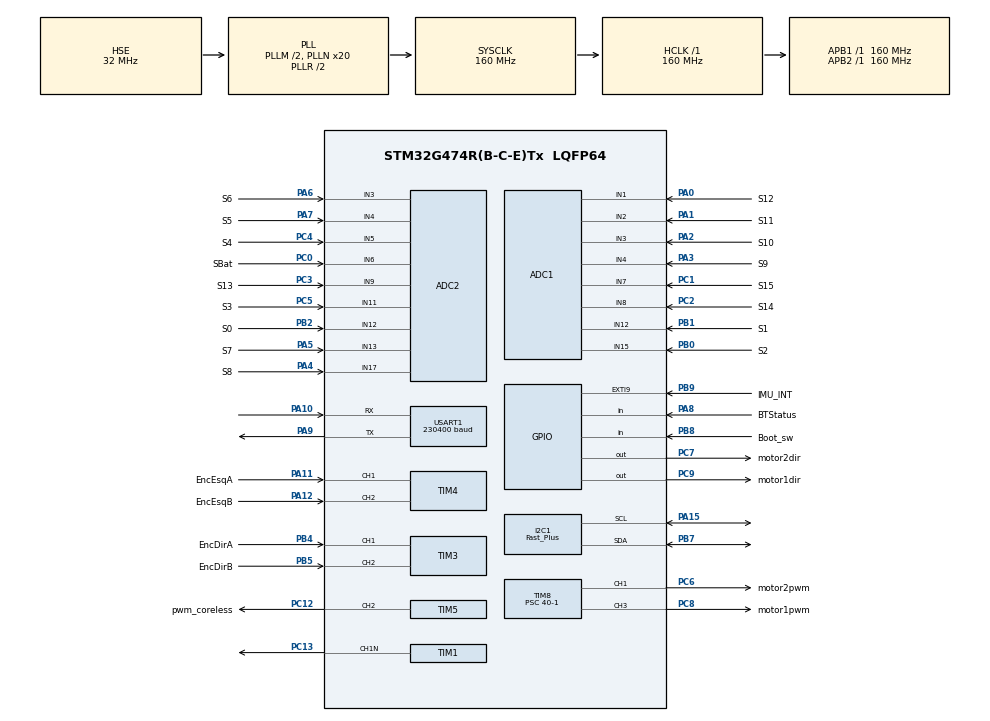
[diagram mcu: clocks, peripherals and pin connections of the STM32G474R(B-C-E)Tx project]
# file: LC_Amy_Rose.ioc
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ADC1.Channel-10\#ChannelRegularConversion=ADC_CHANNEL_VREFINT
ADC1.Channel-2\#ChannelRegularConversion=ADC_CHANNEL_1
ADC1.Channel-3\#ChannelRegularConversion=ADC_CHANNEL_2
ADC1.Channel-4\#ChannelRegularConversion=ADC_CHANNEL_3
ADC1.Channel-5\#ChannelRegularConversion=ADC_CHANNEL_4
ADC1.Channel-6\#ChannelRegularConversion=ADC_CHANNEL_7
ADC1.Channel-7\#ChannelRegularConversion=ADC_CHANNEL_8
ADC1.Channel-8\#ChannelRegularConversion=ADC_CHANNEL_12
ADC1.Channel-9\#ChannelRegularConversion=ADC_CHANNEL_15
ADC1.ContinuousConvMode=ENABLE
ADC1.DMAContinuousRequests=ENABLE
ADC1.NbrOfConversion=9
ADC1.NbrOfConversionFlag=1
ADC1.OffsetNumber-10\#ChannelRegularConversion=ADC_OFFSET_NONE
ADC1.OffsetNumber-2\#ChannelRegularConversion=ADC_OFFSET_NONE
ADC1.OffsetNumber-3\#ChannelRegularConversion=ADC_OFFSET_NONE
ADC1.OffsetNumber-4\#ChannelRegularConversion=ADC_OFFSET_NONE
ADC1.OffsetNumber-5\#ChannelRegularConversion=ADC_OFFSET_NONE
ADC1.OffsetNumber-6\#ChannelRegularConversion=ADC_OFFSET_NONE
ADC1.OffsetNumber-7\#ChannelRegularConversion=ADC_OFFSET_NONE
ADC1.OffsetNumber-8\#ChannelRegularConversion=ADC_OFFSET_NONE
ADC1.OffsetNumber-9\#ChannelRegularConversion=ADC_OFFSET_NONE
ADC1.Rank-10\#ChannelRegularConversion=9
ADC1.Rank-2\#ChannelRegularConversion=1
ADC1.Rank-3\#ChannelRegularConversion=2
ADC1.Rank-4\#ChannelRegularConversion=3
ADC1.Rank-5\#ChannelRegularConversion=4
ADC1.Rank-6\#ChannelRegularConversion=5
ADC1.Rank-7\#ChannelRegularConversion=6
ADC1.Rank-8\#ChannelRegularConversion=7
ADC1.Rank-9\#ChannelRegularConversion=8
ADC1.SamplingTime-10\#ChannelRegularConversion=ADC_SAMPLETIME_640CYCLES_5
ADC1.SamplingTime-2\#ChannelRegularConversion=ADC_SAMPLETIME_640CYCLES_5
ADC1.SamplingTime-3\#ChannelRegularConversion=ADC_SAMPLETIME_640CYCLES_5
ADC1.SamplingTime-4\#ChannelRegularConversion=ADC_SAMPLETIME_640CYCLES_5
ADC1.SamplingTime-5\#ChannelRegularConversion=ADC_SAMPLETIME_640CYCLES_5
ADC1.SamplingTime-6\#ChannelRegularConversion=ADC_SAMPLETIME_640CYCLES_5
ADC1.SamplingTime-7\#ChannelRegularConversion=ADC_SAMPLETIME_640CYCLES_5
ADC1.SamplingTime-8\#ChannelRegularConversion=ADC_SAMPLETIME_640CYCLES_5
ADC1.SamplingTime-9\#ChannelRegularConversion=ADC_SAMPLETIME_640CYCLES_5
ADC1.master=1
ADC2.Channel-0\#ChannelRegularConversion=ADC_CHANNEL_3
ADC2.Channel-1\#ChannelRegularConversion=ADC_CHANNEL_4
ADC2.Channel-2\#ChannelRegularConversion=ADC_CHANNEL_5
ADC2.Channel-3\#ChannelRegularConversion=ADC_CHANNEL_9
ADC2.Channel-4\#ChannelRegularConversion=ADC_CHANNEL_11
ADC2.Channel-5\#ChannelRegularConversion=ADC_CHANNEL_12
ADC2.Channel-6\#ChannelRegularConversion=ADC_CHANNEL_13
ADC2.Channel-7\#ChannelRegularConversion=ADC_CHANNEL_17
ADC2.Channel-8\#ChannelRegularConversion=ADC_CHANNEL_6
ADC2.ContinuousConvMode=ENABLE
ADC2.DMAContinuousRequests=ENABLE
ADC2.NbrOfConversion=9
ADC2.NbrOfConversionFlag=1
ADC2.OffsetNumber-0\#ChannelRegularConversion=ADC_OFFSET_NONE
ADC2.OffsetNumber-1\#ChannelRegularConversion=ADC_OFFSET_NONE
ADC2.OffsetNumber-2\#ChannelRegularConversion=ADC_OFFSET_NONE
ADC2.OffsetNumber-3\#ChannelRegularConversion=ADC_OFFSET_NONE
ADC2.OffsetNumber-4\#ChannelRegularConversion=ADC_OFFSET_NONE
ADC2.OffsetNumber-5\#ChannelRegularConversion=ADC_OFFSET_NONE
ADC2.OffsetNumber-6\#ChannelRegularConversion=ADC_OFFSET_NONE
ADC2.OffsetNumber-7\#ChannelRegularConversion=ADC_OFFSET_NONE
ADC2.OffsetNumber-8\#ChannelRegularConversion=ADC_OFFSET_NONE
ADC2.Rank-0\#ChannelRegularConversion=1
ADC2.Rank-1\#ChannelRegularConversion=2
ADC2.Rank-2\#ChannelRegularConversion=3
ADC2.Rank-3\#ChannelRegularConversion=4
ADC2.Rank-4\#ChannelRegularConversion=5
ADC2.Rank-5\#ChannelRegularConversion=6
ADC2.Rank-6\#ChannelRegularConversion=7
ADC2.Rank-7\#ChannelRegularConversion=8
ADC2.Rank-8\#ChannelRegularConversion=9
ADC2.SamplingTime-0\#ChannelRegularConversion=ADC_SAMPLETIME_640CYCLES_5
ADC2.SamplingTime-1\#ChannelRegularConversion=ADC_SAMPLETIME_640CYCLES_5
ADC2.SamplingTime-2\#ChannelRegularConversion=ADC_SAMPLETIME_640CYCLES_5
ADC2.SamplingTime-3\#ChannelRegularConversion=ADC_SAMPLETIME_640CYCLES_5
ADC2.SamplingTime-4\#ChannelRegularConversion=ADC_SAMPLETIME_640CYCLES_5
ADC2.SamplingTime-5\#ChannelRegularConversion=ADC_SAMPLETIME_640CYCLES_5
ADC2.SamplingTime-6\#ChannelRegularConversion=ADC_SAMPLETIME_640CYCLES_5
ADC2.SamplingTime-7\#ChannelRegularConversion=ADC_SAMPLETIME_640CYCLES_5
ADC2.SamplingTime-8\#ChannelRegularConversion=ADC_SAMPLETIME_640CYCLES_5
Dma.ADC1.0.Direction=DMA_PERIPH_TO_MEMORY
Dma.ADC1.0.EventEnable=DISABLE
Dma.ADC1.0.Instance=DMA1_Channel1
Dma.ADC1.0.MemDataAlignment=DMA_MDATAALIGN_WORD
Dma.ADC1.0.MemInc=DMA_MINC_ENABLE
Dma.ADC1.0.Mode=DMA_CIRCULAR
Dma.ADC1.0.PeriphDataAlignment=DMA_PDATAALIGN_WORD
Dma.ADC1.0.PeriphInc=DMA_PINC_DISABLE
Dma.ADC1.0.Polarity=HAL_DMAMUX_REQ_GEN_RISING
Dma.ADC1.0.Priority=DMA_PRIORITY_LOW
Dma.ADC1.0.RequestNumber=1
Dma.ADC1.0.SignalID=NONE
Dma.ADC1.0.SyncEnable=DISABLE
Dma.ADC1.0.SyncPolarity=HAL_DMAMUX_SYNC_NO_EVENT
Dma.ADC1.0.SyncRequestNumber=1
Dma.ADC1.0.SyncSignalID=NONE
Dma.ADC2.1.Direction=DMA_PERIPH_TO_MEMORY
Dma.ADC2.1.EventEnable=DISABLE
Dma.ADC2.1.Instance=DMA1_Channel2
Dma.ADC2.1.MemDataAlignment=DMA_MDATAALIGN_WORD
Dma.ADC2.1.MemInc=DMA_MINC_ENABLE
Dma.ADC2.1.Mode=DMA_CIRCULAR
Dma.ADC2.1.PeriphDataAlignment=DMA_PDATAALIGN_WORD
Dma.ADC2.1.PeriphInc=DMA_PINC_DISABLE
Dma.ADC2.1.Polarity=HAL_DMAMUX_REQ_GEN_RISING
Dma.ADC2.1.Priority=DMA_PRIORITY_LOW
Dma.ADC2.1.RequestNumber=1
Dma.ADC2.1.SignalID=NONE
Dma.ADC2.1.SyncEnable=DISABLE
Dma.ADC2.1.SyncPolarity=HAL_DMAMUX_SYNC_NO_EVENT
Dma.ADC2.1.SyncRequestNumber=1
Dma.ADC2.1.SyncSignalID=NONE
Dma.Request0=ADC1
Dma.Request1=ADC2
Dma.Request2=USART1_TX
Dma.Request3=USART1_RX
Dma.Request4=TIM1_CH1
Dma.TIM1_CH1.4.Direction=DMA_MEMORY_TO_PERIPH
Dma.TIM1_CH1.4.EventEnable=DISABLE
Dma.TIM1_CH1.4.Instance=DMA1_Channel5
Dma.TIM1_CH1.4.MemDataAlignment=DMA_MDATAALIGN_WORD
Dma.TIM1_CH1.4.MemInc=DMA_MINC_ENABLE
Dma.TIM1_CH1.4.Mode=DMA_NORMAL
Dma.TIM1_CH1.4.PeriphDataAlignment=DMA_PDATAALIGN_WORD
Dma.TIM1_CH1.4.PeriphInc=DMA_PINC_DISABLE
Dma.TIM1_CH1.4.Polarity=HAL_DMAMUX_REQ_GEN_RISING
Dma.TIM1_CH1.4.Priority=DMA_PRIORITY_LOW
Dma.TIM1_CH1.4.RequestNumber=1
Dma.TIM1_CH1.4.SignalID=NONE
Dma.TIM1_CH1.4.SyncEnable=DISABLE
Dma.TIM1_CH1.4.SyncPolarity=HAL_DMAMUX_SYNC_NO_EVENT
Dma.TIM1_CH1.4.SyncRequestNumber=1
Dma.TIM1_CH1.4.SyncSignalID=NONE
Dma.USART1_RX.3.Direction=DMA_PERIPH_TO_MEMORY
Dma.USART1_RX.3.EventEnable=DISABLE
Dma.USART1_RX.3.Instance=DMA1_Channel4
Dma.USART1_RX.3.MemDataAlignment=DMA_MDATAALIGN_BYTE
Dma.USART1_RX.3.MemInc=DMA_MINC_ENABLE
Dma.USART1_RX.3.Mode=DMA_NORMAL
Dma.USART1_RX.3.PeriphDataAlignment=DMA_PDATAALIGN_BYTE
Dma.USART1_RX.3.PeriphInc=DMA_PINC_DISABLE
Dma.USART1_RX.3.Polarity=HAL_DMAMUX_REQ_GEN_RISING
Dma.USART1_RX.3.Priority=DMA_PRIORITY_LOW
Dma.USART1_RX.3.RequestNumber=1
Dma.USART1_RX.3.SignalID=NONE
Dma.USART1_RX.3.SyncEnable=DISABLE
Dma.USART1_RX.3.SyncPolarity=HAL_DMAMUX_SYNC_NO_EVENT
Dma.USART1_RX.3.SyncRequestNumber=1
Dma.USART1_RX.3.SyncSignalID=NONE
Dma.USART1_TX.2.Direction=DMA_MEMORY_TO_PERIPH
Dma.USART1_TX.2.EventEnable=DISABLE
Dma.USART1_TX.2.Instance=DMA1_Channel3
Dma.USART1_TX.2.MemDataAlignment=DMA_MDATAALIGN_BYTE
Dma.USART1_TX.2.MemInc=DMA_MINC_ENABLE
Dma.USART1_TX.2.Mode=DMA_NORMAL
Dma.USART1_TX.2.PeriphDataAlignment=DMA_PDATAALIGN_BYTE
Dma.USART1_TX.2.PeriphInc=DMA_PINC_DISABLE
Dma.USART1_TX.2.Polarity=HAL_DMAMUX_REQ_GEN_RISING
Dma.USART1_TX.2.Priority=DMA_PRIORITY_LOW
Dma.USART1_TX.2.RequestNumber=1
Dma.USART1_TX.2.SignalID=NONE
Dma.USART1_TX.2.SyncEnable=DISABLE
Dma.USART1_TX.2.SyncPolarity=HAL_DMAMUX_SYNC_NO_EVENT
Dma.USART1_TX.2.SyncRequestNumber=1
Dma.USART1_TX.2.SyncSignalID=NONE
I2C1.I2C_Speed_Mode=I2C_Fast_Plus
I2C1.Timing=0x10B30F25
Mcu.Family=STM32G4
Mcu.Name=STM32G474R(B-C-E)Tx
Mcu.Package=LQFP64
NVIC.ADC1_2_IRQn=true\:0\:0\:false\:false\:true\:true\:true\:true
NVIC.DMA1_Channel1_IRQn=true\:0\:0\:false\:false\:true\:false\:true\:true
NVIC.DMA1_Channel2_IRQn=true\:0\:0\:false\:false\:true\:false\:true\:true
NVIC.DMA1_Channel3_IRQn=true\:0\:0\:false\:false\:true\:false\:true\:true
NVIC.DMA1_Channel4_IRQn=true\:0\:0\:false\:false\:true\:false\:true\:true
NVIC.DMA1_Channel5_IRQn=true\:0\:0\:false\:false\:true\:false\:true\:true
NVIC.PriorityGroup=NVIC_PRIORITYGROUP_4
NVIC.TIM1_BRK_TIM15_IRQn=true\:0\:0\:false\:false\:true\:true\:true\:true
NVIC.TIM1_CC_IRQn=true\:0\:0\:false\:false\:true\:true\:true\:true
NVIC.TIM1_TRG_COM_TIM17_IRQn=true\:0\:0\:false\:false\:true\:true\:true\:true
NVIC.TIM1_UP_TIM16_IRQn=true\:0\:0\:false\:false\:true\:true\:true\:true
NVIC.TIM3_IRQn=true\:0\:0\:false\:false\:true\:true\:true\:true
NVIC.TIM4_IRQn=true\:0\:0\:false\:false\:true\:true\:true\:true
NVIC.TIM6_DAC_IRQn=true\:15\:0\:false\:false\:true\:false\:true\:true
NVIC.TimeBase=TIM6_DAC_IRQn
NVIC.TimeBaseIP=TIM6
NVIC.USART1_IRQn=true\:0\:0\:false\:false\:true\:true\:true\:true
PA0.GPIO_Label=S12
PA0.Mode=IN1-Single-Ended
PA0.Signal=ADC1_IN1
PA1.GPIO_Label=S11
PA1.Mode=IN2-Single-Ended
PA1.Signal=ADC1_IN2
PA10.Mode=Asynchronous
PA10.Signal=USART1_RX
PA11.GPIO_Label=EncEsqA
PA11.GPIO_PuPd=GPIO_PULLUP
PA11.Signal=S_TIM4_CH1
PA12.GPIO_Label=EncEsqB
PA12.GPIO_PuPd=GPIO_PULLUP
PA12.Signal=S_TIM4_CH2
PA13.Mode=Serial_Wire
PA13.Signal=SYS_JTMS-SWDIO
PA14.Mode=Serial_Wire
PA14.Signal=SYS_JTCK-SWCLK
PA15.Mode=I2C
PA15.Signal=I2C1_SCL
PA2.GPIO_Label=S10
PA2.Mode=IN3-Single-Ended
PA2.Signal=ADC1_IN3
PA3.GPIO_Label=S9
PA3.Mode=IN4-Single-Ended
PA3.Signal=ADC1_IN4
PA4.GPIO_Label=S8
PA4.Mode=IN17-Single-Ended
PA4.Signal=ADC2_IN17
PA5.GPIO_Label=S7
PA5.Mode=IN13-Single-Ended
PA5.Signal=ADC2_IN13
PA6.GPIO_Label=S6
PA6.Mode=IN3-Single-Ended
PA6.Signal=ADC2_IN3
PA7.GPIO_Label=S5
PA7.Mode=IN4-Single-Ended
PA7.Signal=ADC2_IN4
PA8.GPIO_Label=BTStatus
PA8.Signal=GPIO_Input
PA9.Mode=Asynchronous
PA9.Signal=USART1_TX
PB0.GPIO_Label=S2
PB0.Mode=IN15-Single-Ended
PB0.Signal=ADC1_IN15
PB1.GPIO_Label=S1
PB1.Mode=IN12-Single-Ended
PB1.Signal=ADC1_IN12
PB2.GPIO_Label=S0
PB2.Mode=IN12-Single-Ended
PB2.Signal=ADC2_IN12
PB4.GPIO_Label=EncDirA
PB4.GPIO_PuPd=GPIO_PULLUP
PB4.Signal=S_TIM3_CH1
PB5.GPIO_Label=EncDirB
PB5.GPIO_PuPd=GPIO_PULLUP
PB5.Signal=S_TIM3_CH2
PB7.Mode=I2C
PB7.Signal=I2C1_SDA
PB8-BOOT0.GPIO_Label=Boot_sw
PB8-BOOT0.GPIO_PuPd=GPIO_PULLDOWN
PB8-BOOT0.Signal=GPIO_Input
PB9.GPIO_Label=IMU_INT
PB9.Signal=GPXTI9
PC0.GPIO_Label=SBat
PC0.Mode=IN6-Single-Ended
PC0.Signal=ADC2_IN6
PC1.GPIO_Label=S15
PC1.Mode=IN7-Single-Ended
PC1.Signal=ADC1_IN7
PC12.GPIO_Label=pwm_coreless
PC12.GPIO_PuPd=GPIO_NOPULL
PC12.Signal=S_TIM5_CH2
PC13.Mode=PWM Generation1 CH1N
PC13.Signal=TIM1_CH1N
PC2.GPIO_Label=S14
PC2.Mode=IN8-Single-Ended
PC2.Signal=ADC1_IN8
PC3.GPIO_Label=S13
PC3.Mode=IN9-Single-Ended
PC3.Signal=ADC2_IN9
PC4.GPIO_Label=S4
PC4.Mode=IN5-Single-Ended
PC4.Signal=ADC2_IN5
PC5.GPIO_Label=S3
PC5.Mode=IN11-Single-Ended
PC5.Signal=ADC2_IN11
PC6.GPIO_Label=motor2pwm
PC6.GPIO_PuPd=GPIO_NOPULL
PC6.Signal=S_TIM8_CH1
PC7.GPIO_Label=motor2dir
PC7.Signal=GPIO_Output
PC8.GPIO_Label=motor1pwm
PC8.GPIO_PuPd=GPIO_NOPULL
PC8.Signal=S_TIM8_CH3
PC9.GPIO_Label=motor1dir
PC9.Signal=GPIO_Output
PF0-OSC_IN.Mode=HSE-External-Oscillator
PF0-OSC_IN.Signal=RCC_OSC_IN
PF1-OSC_OUT.Mode=HSE-External-Oscillator
PF1-OSC_OUT.Signal=RCC_OSC_OUT
ProjectManager.HeapSize=0x200
ProjectManager.StackSize=0x400
ProjectManager.TargetToolchain=STM32CubeIDE
RCC.ADC12Freq_Value=160000000
RCC.ADC345Freq_Value=160000000
RCC.AHBFreq_Value=160000000
RCC.APB1Freq_Value=160000000
RCC.APB1TimFreq_Value=160000000
RCC.APB2Freq_Value=160000000
RCC.APB2TimFreq_Value=160000000
RCC.CortexFreq_Value=160000000
RCC.EXTERNAL_CLOCK_VALUE=12288000
RCC.HCLKFreq_Value=160000000
RCC.HSE_VALUE=32000000
RCC.HSI48_VALUE=48000000
RCC.HSI_VALUE=16000000
RCC.LSE_VALUE=32768
RCC.PLLM=RCC_PLLM_DIV2
RCC.PLLN=20
RCC.PLLSourceVirtual=RCC_PLLSOURCE_HSE
RCC.SYSCLKFreq_VALUE=160000000
RCC.SYSCLKSource=RCC_SYSCLKSOURCE_PLLCLK
RCC.USBFreq_Value=160000000
RCC.VCOOutputFreq_Value=320000000
SH.S_TIM3_CH1.0=TIM3_CH1,Encoder_Interface
SH.S_TIM3_CH2.0=TIM3_CH2,Encoder_Interface
SH.S_TIM4_CH1.0=TIM4_CH1,Encoder_Interface
SH.S_TIM4_CH2.0=TIM4_CH2,Encoder_Interface
SH.S_TIM5_CH2.0=TIM5_CH2,PWM Generation2 CH2
SH.S_TIM8_CH1.0=TIM8_CH1,PWM Generation1 CH1
SH.S_TIM8_CH3.0=TIM8_CH3,PWM Generation3 CH3
TIM1.Channel-PWM\ Generation1\ CH1N=TIM_CHANNEL_1
TIM1.PeriodNoDither=5-1
TIM1.Prescaler=5-1
TIM2.Prescaler=16-1
TIM3.CounterMode=TIM_COUNTERMODE_UP
TIM3.EncoderMode=TIM_ENCODERMODE_TI12
TIM3.IC1Polarity=TIM_ICPOLARITY_FALLING
TIM3.IC2Polarity=TIM_ICPOLARITY_RISING
TIM4.AutoReloadPreload=TIM_AUTORELOAD_PRELOAD_DISABLE
TIM4.CounterMode=TIM_COUNTERMODE_UP
TIM4.EncoderMode=TIM_ENCODERMODE_TI12
TIM4.IC1Polarity=TIM_ICPOLARITY_RISING
TIM4.IC2Polarity=TIM_ICPOLARITY_RISING
TIM5.Channel-PWM\ Generation2\ CH2=TIM_CHANNEL_2
TIM5.PeriodNoDither=1000-1
TIM5.Prescaler=40-1
TIM8.Channel-PWM\ Generation1\ CH1=TIM_CHANNEL_1
TIM8.Channel-PWM\ Generation3\ CH3=TIM_CHANNEL_3
TIM8.PeriodNoDither=1000-1
TIM8.Prescaler=40-1
USART1.BaudRate=230400
USART1.VirtualMode-Asynchronous=VM_ASYNC
VP_ADC1_Vref_Input.Mode=IN-Vrefint
VP_SYS_VS_DBSignals.Mode=DisableDeadBatterySignals
VP_SYS_VS_tim6.Mode=TIM6
VP_TIM1_VS_ClockSourceINT.Mode=Internal
VP_TIM2_VS_ClockSourceINT.Mode=Internal
VP_TIM5_VS_ClockSourceINT.Mode=Internal
VP_TIM8_VS_ClockSourceINT.Mode=Internal
board=custom

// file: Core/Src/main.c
/* USER CODE BEGIN Header */
/**
  ******************************************************************************
  * @file           : main.c
  * @brief          : Main program body
  ******************************************************************************
  * @attention
  *
  * Copyright (c) 2026 STMicroelectronics.
  * All rights reserved.
  *
  * This software is licensed under terms that can be found in the LICENSE file
  * in the root directory of this software component.
  * If no LICENSE file comes with this software, it is provided AS-IS.
  *
  ******************************************************************************
  */
/* USER CODE END Header */
#include "main.h"
#include "adc.h"
#include "dma.h"
#include "i2c.h"
#include "tim.h"
#include "usart.h"
#include "gpio.h"

/* USER CODE BEGIN Includes */
#include "../../Robot/robot.h"
/* USER CODE END Includes */

void SystemClock_Config(void);

int main(void)
{

  /* MCU Configuration--------------------------------------------------------*/

  /* Reset of all peripherals, Initializes the Flash interface and the Systick. */
  HAL_Init();

  /* Configure the system clock */
  SystemClock_Config();

  /* Initialize all configured peripherals */
  MX_GPIO_Init();
  MX_DMA_Init();
  MX_TIM8_Init();
  MX_ADC1_Init();
  MX_ADC2_Init();
  MX_TIM3_Init();
  MX_TIM4_Init();
  MX_TIM5_Init();
  MX_USART1_UART_Init();
  MX_I2C1_Init();
  MX_TIM2_Init();
  MX_TIM1_Init();
  /* USER CODE BEGIN 2 */
  setup();
  /* USER CODE END 2 */

  /* Infinite loop */
  while (1)
  {

    /* USER CODE BEGIN 3 */
    loop();
  }
  /* USER CODE END 3 */
}

void SystemClock_Config(void)
{
  RCC_OscInitTypeDef RCC_OscInitStruct = {0};
  RCC_ClkInitTypeDef RCC_ClkInitStruct = {0};

  /** Configure the main internal regulator output voltage
  */
  HAL_PWREx_ControlVoltageScaling(PWR_REGULATOR_VOLTAGE_SCALE1_BOOST);

  /** Initializes the RCC Oscillators according to the specified parameters
  * in the RCC_OscInitTypeDef structure.
  */
  RCC_OscInitStruct.OscillatorType = RCC_OSCILLATORTYPE_HSE;
  RCC_OscInitStruct.HSEState = RCC_HSE_ON;
  RCC_OscInitStruct.PLL.PLLState = RCC_PLL_ON;
  RCC_OscInitStruct.PLL.PLLSource = RCC_PLLSOURCE_HSE;
  RCC_OscInitStruct.PLL.PLLM = RCC_PLLM_DIV2;
  RCC_OscInitStruct.PLL.PLLN = 20;
  RCC_OscInitStruct.PLL.PLLP = RCC_PLLP_DIV2;
  RCC_OscInitStruct.PLL.PLLQ = RCC_PLLQ_DIV2;
  RCC_OscInitStruct.PLL.PLLR = RCC_PLLR_DIV2;
  if (HAL_RCC_OscConfig(&RCC_OscInitStruct) != HAL_OK)
  {
    Error_Handler();
  }

  /** Initializes the CPU, AHB and APB buses clocks
  */
  RCC_ClkInitStruct.ClockType = RCC_CLOCKTYPE_HCLK|RCC_CLOCKTYPE_SYSCLK
                              |RCC_CLOCKTYPE_PCLK1|RCC_CLOCKTYPE_PCLK2;
  RCC_ClkInitStruct.SYSCLKSource = RCC_SYSCLKSOURCE_PLLCLK;
  RCC_ClkInitStruct.AHBCLKDivider = RCC_SYSCLK_DIV1;
  RCC_ClkInitStruct.APB1CLKDivider = RCC_HCLK_DIV1;
  RCC_ClkInitStruct.APB2CLKDivider = RCC_HCLK_DIV1;

  if (HAL_RCC_ClockConfig(&RCC_ClkInitStruct, FLASH_LATENCY_4) != HAL_OK)
  {
    Error_Handler();
  }
}

void HAL_TIM_PeriodElapsedCallback(TIM_HandleTypeDef *htim)
{
  if (htim->Instance == TIM6)
  {
    HAL_IncTick();
  }
}

void Error_Handler(void)
{
  __disable_irq();
  while (1)
  {
  }
}
